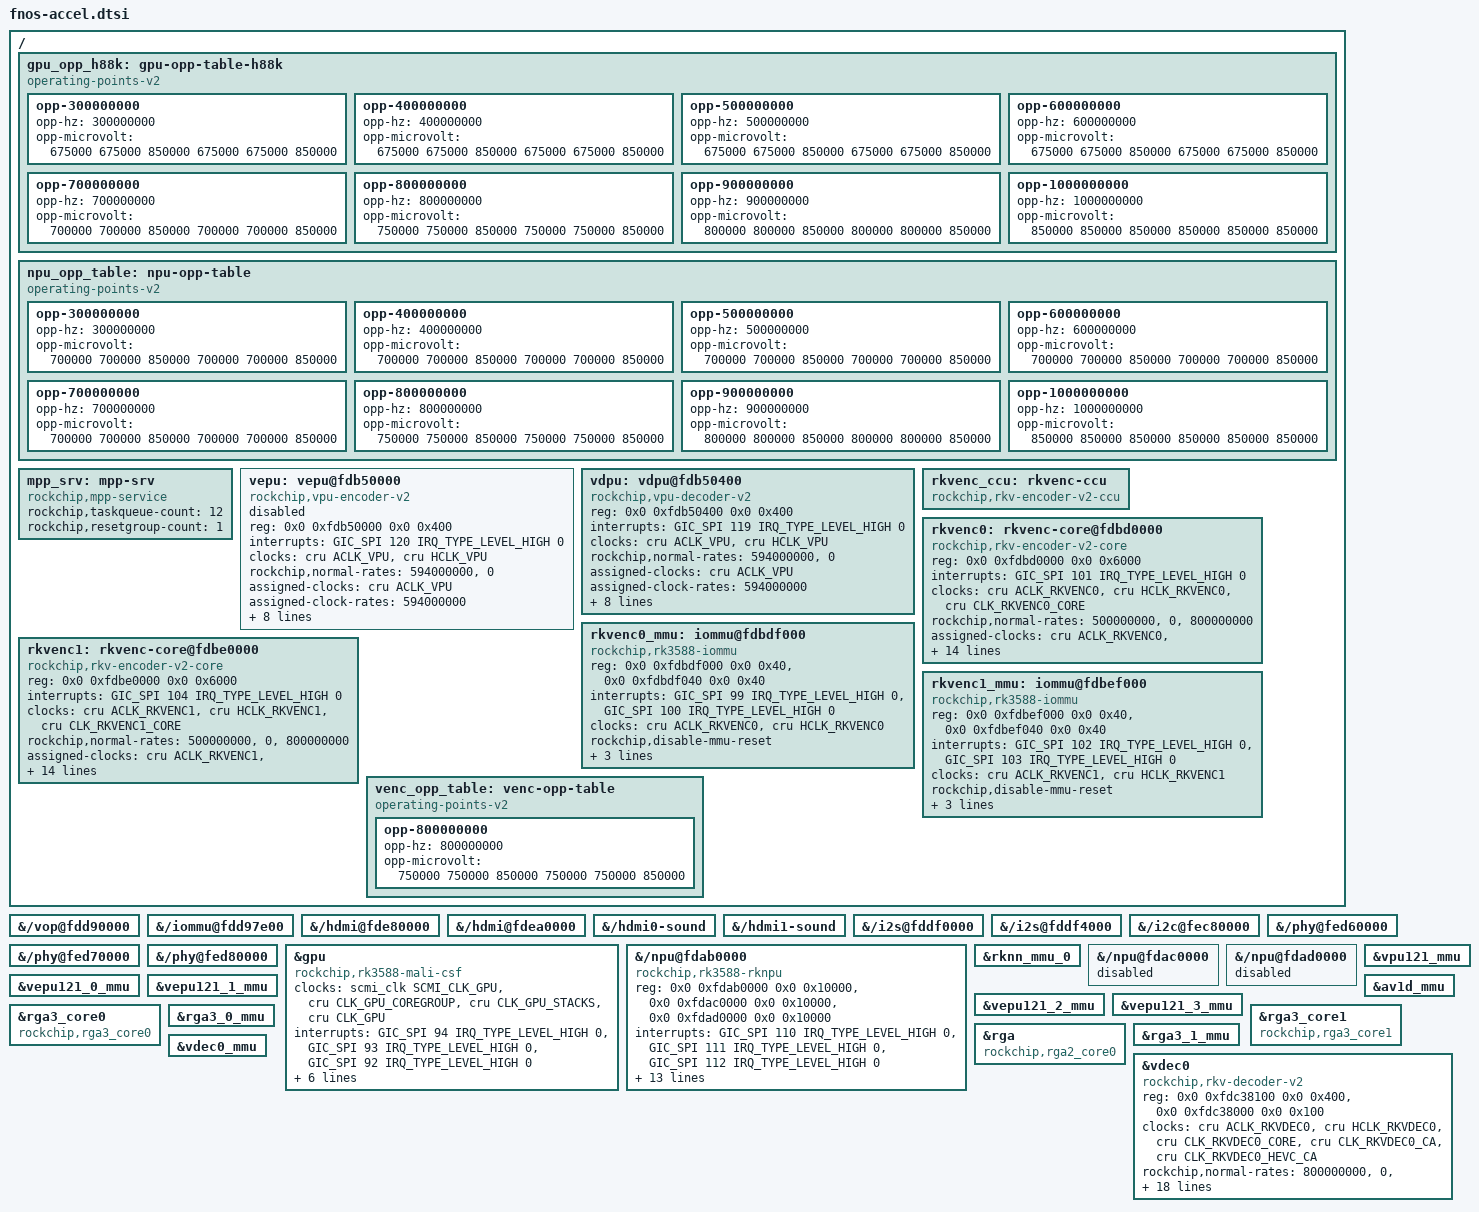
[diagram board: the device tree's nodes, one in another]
/* 对齐「真·官方 T6 DTB」的多媒体/加速器节点。
 *
 * 依据（2026-10-27 实机取证，refs/t6-official.dtb = t6.img p1 原件，sha256 09425cc7…）：
 *   飞牛内核 6.18.18.c1145-trim 的多媒体驱动是 Rockchip BSP 树外模块：
 *     updates/trim/rk_gpu/rkgpu_bifrost_csf.ko   of_match = rockchip,rk3588-mali-csf / arm,mali-valhall
 *     updates/trim/rk_vcodec/rknpu.ko            of_match = rockchip,rk3588-rknpu
 *     updates/trim/rk_vcodec/rk_vcodec.ko        of_match = rockchip,mpp-service（顶层 mpp-srv 节点）
 *     updates/trim/rk_vcodec/rga3.ko             of_match = rockchip,rga3_core0 / rga3_core1 / rga2_core0
 *   而主线 rk3588-base.dtsi 写的是 arm,mali-valhall-csf / rockchip,rk3588-rknn-core /
 *   rockchip,rk3588-rga3，且完全没有 mpp-srv 节点 —— 于是三个驱动都注册成功却 0 设备绑定，
 *   表现为：无 /dev/dri、无 /dev/rknpu、无 /dev/mpp_service。
 *   本文件把这些节点按真 T6 DTB 的命名/属性/中断顺序覆盖回来（硬件地址、时钟、电源域
 *   与主线 dtsi 一致，只改驱动认得的命名与必需属性）。
 */

/* ---------------- 显示通路（保持开启） ---------------- */
&{/vop@fdd90000} { status = "okay"; };
&{/iommu@fdd97e00} { status = "okay"; };
&{/hdmi@fde80000} { status = "okay"; };
&{/hdmi@fdea0000} { status = "okay"; };
&{/hdmi0-sound} { status = "okay"; };
&{/hdmi1-sound} { status = "okay"; };
&{/i2s@fddf0000} { status = "okay"; };
&{/i2s@fddf4000} { status = "okay"; };
&{/i2c@fec80000} { status = "okay"; };
&{/phy@fed60000} { status = "okay"; };
&{/phy@fed70000} { status = "okay"; };
&{/phy@fed80000} { status = "okay"; };

/* ---------------- GPU：BSP kbase (Bifrost CSF) ----------------
 * 真 T6：compatible = rockchip,rk3588-mali-csf + arm,mali-valhall
 *        clock-names = clk_mali / clk_gpu_coregroup / clk_gpu_stacks / clk_gpu  （4 个）
 *        interrupt-names = GPU / MMU / JOB （对应 SPI 94 / 93 / 92）
 *        mali-supply / mem-supply = vdd_gpu_s0
 */
&gpu {
	compatible = "rockchip,rk3588-mali-csf", "arm,mali-valhall";
	clocks = <&scmi_clk SCMI_CLK_GPU>, <&cru CLK_GPU_COREGROUP>,
		 <&cru CLK_GPU_STACKS>, <&cru CLK_GPU>;
	clock-names = "clk_mali", "clk_gpu_coregroup", "clk_gpu_stacks", "clk_gpu";
	interrupts = <GIC_SPI 94 IRQ_TYPE_LEVEL_HIGH 0>,
		     <GIC_SPI 93 IRQ_TYPE_LEVEL_HIGH 0>,
		     <GIC_SPI 92 IRQ_TYPE_LEVEL_HIGH 0>;
	interrupt-names = "GPU", "MMU", "JOB";
	mali-supply = <&vdd_gpu_s0>;
	mem-supply = <&vdd_gpu_s0>;
	upthreshold = <60>;
	downdifferential = <30>;
	power-off-delay-ms = <200>;
	operating-points-v2 = <&gpu_opp_h88k>;
	status = "okay";
};

/* GPU 的 opp 表：照官方 T6 的 /gpu-opp-table（8 档，microvolt 6 值＝mali-supply + mem-supply
 * 各 min/target/max）。缺这张表 GPU 报 _of_add_opp_table_v2: Failed to add OPP, -22。
 */
/ {
	gpu_opp_h88k: gpu-opp-table-h88k {
		compatible = "operating-points-v2";
		opp-300000000  { opp-hz = /bits/ 64 <300000000>;  opp-microvolt = <675000 675000 850000 675000 675000 850000>; };
		opp-400000000  { opp-hz = /bits/ 64 <400000000>;  opp-microvolt = <675000 675000 850000 675000 675000 850000>; };
		opp-500000000  { opp-hz = /bits/ 64 <500000000>;  opp-microvolt = <675000 675000 850000 675000 675000 850000>; };
		opp-600000000  { opp-hz = /bits/ 64 <600000000>;  opp-microvolt = <675000 675000 850000 675000 675000 850000>; };
		opp-700000000  { opp-hz = /bits/ 64 <700000000>;  opp-microvolt = <700000 700000 850000 700000 700000 850000>; };
		opp-800000000  { opp-hz = /bits/ 64 <800000000>;  opp-microvolt = <750000 750000 850000 750000 750000 850000>; };
		opp-900000000  { opp-hz = /bits/ 64 <900000000>;  opp-microvolt = <800000 800000 850000 800000 800000 850000>; };
		opp-1000000000 { opp-hz = /bits/ 64 <1000000000>; opp-microvolt = <850000 850000 850000 850000 850000 850000>; };
	};
};


/ {
	npu_opp_table: npu-opp-table {
		compatible = "operating-points-v2";
		/* 数值照官方 T6 DTB 的 npu-opp-table（supported-hw=0xe9 那一组基础档；
		 * pvtm/nvmem 校准属性省略——本板 efuse 里没有 npu-opp-info 子节点） */
		opp-300000000  { opp-hz = /bits/ 64 <300000000>;  opp-microvolt = <700000 700000 850000 700000 700000 850000>; };
		opp-400000000  { opp-hz = /bits/ 64 <400000000>;  opp-microvolt = <700000 700000 850000 700000 700000 850000>; };
		opp-500000000  { opp-hz = /bits/ 64 <500000000>;  opp-microvolt = <700000 700000 850000 700000 700000 850000>; };
		opp-600000000  { opp-hz = /bits/ 64 <600000000>;  opp-microvolt = <700000 700000 850000 700000 700000 850000>; };
		opp-700000000  { opp-hz = /bits/ 64 <700000000>;  opp-microvolt = <700000 700000 850000 700000 700000 850000>; };
		opp-800000000  { opp-hz = /bits/ 64 <800000000>;  opp-microvolt = <750000 750000 850000 750000 750000 850000>; };
		opp-900000000  { opp-hz = /bits/ 64 <900000000>;  opp-microvolt = <800000 800000 850000 800000 800000 850000>; };
		opp-1000000000 { opp-hz = /bits/ 64 <1000000000>; opp-microvolt = <850000 850000 850000 850000 850000 850000>; };
	};
};

/* ---------------- NPU：BSP rknpu（三核一个设备） ----------------
 * 真 T6：compatible = rockchip,rk3588-rknpu；reg 三段各 64KiB（pc/cna/core）；
 *        3 个中断、8 个时钟、6 个复位、3 个电源域。
 */
&{/npu@fdab0000} {
	compatible = "rockchip,rk3588-rknpu";
	reg = <0x0 0xfdab0000 0x0 0x10000>,
	      <0x0 0xfdac0000 0x0 0x10000>,
	      <0x0 0xfdad0000 0x0 0x10000>;
	reg-names = "pc", "cna", "core";
	interrupts = <GIC_SPI 110 IRQ_TYPE_LEVEL_HIGH 0>,
		     <GIC_SPI 111 IRQ_TYPE_LEVEL_HIGH 0>,
		     <GIC_SPI 112 IRQ_TYPE_LEVEL_HIGH 0>;
	interrupt-names = "npu0_irq", "npu1_irq", "npu2_irq";
	clocks = <&scmi_clk SCMI_CLK_NPU>,
		 <&cru ACLK_NPU0>, <&cru ACLK_NPU1>, <&cru ACLK_NPU2>,
		 <&cru HCLK_NPU0>, <&cru HCLK_NPU1>, <&cru HCLK_NPU2>,
		 <&cru PCLK_NPU_ROOT>;
	clock-names = "clk_npu", "aclk0", "aclk1", "aclk2",
		      "hclk0", "hclk1", "hclk2", "pclk";
	resets = <&cru SRST_A_RKNN0>, <&cru SRST_A_RKNN1>, <&cru SRST_A_RKNN2>,
		 <&cru SRST_H_RKNN0>, <&cru SRST_H_RKNN1>, <&cru SRST_H_RKNN2>;
	reset-names = "srst_a0", "srst_a1", "srst_a2", "srst_h0", "srst_h1", "srst_h2";
	power-domains = <&power RK3588_PD_NPUTOP>, <&power RK3588_PD_NPU1>,
			<&power RK3588_PD_NPU2>;
	power-domain-names = "npu0", "npu1", "npu2";
	iommus = <&rknn_mmu_0>;
	rknpu-supply = <&vdd_npu_s0>;
	mem-supply = <&vdd_npu_s0>;
	operating-points-v2 = <&npu_opp_table>;
	status = "okay";
};

&rknn_mmu_0 { status = "okay"; };
/* 独立的两颗核节点不再单独启用（BSP 驱动把三核当一个设备） */
&{/npu@fdac0000} { status = "disabled"; };
&{/npu@fdad0000} { status = "disabled"; };

/* ---------------- VPU / MPP 服务 ----------------
 * rk_vcodec.ko 只认顶层 mpp-srv（rockchip,mpp-service），
 * 主线 dtsi 完全没有这个节点 → /dev/mpp_service 永远不出现。
 */
/ {
	mpp_srv: mpp-srv {
		compatible = "rockchip,mpp-service";
		rockchip,taskqueue-count = <12>;
		rockchip,resetgroup-count = <1>;
		status = "okay";
	};
};

/* 各编解码核的 IOMMU 全开（真 T6 里都是 okay） */
&vpu121_mmu { status = "okay"; };
&vepu121_0_mmu { status = "okay"; };
&vepu121_1_mmu { status = "okay"; };
&vepu121_2_mmu { status = "okay"; };
&vepu121_3_mmu { status = "okay"; };
&av1d_mmu { status = "okay"; };

/* ---------------- RGA：BSP rga3 ----------------
 * 真 T6：fdb60000 = rga3_core0、fdb70000 = rga3_core1、fdb80000 = rga2_core0，
 *        时钟名 aclk_rga3_0 / hclk_rga3_0 / clk_rga3_0 等（主线写 aclk/hclk/sclk）。
 */
&rga3_core0 {
	compatible = "rockchip,rga3_core0";
	clock-names = "aclk_rga3_0", "hclk_rga3_0", "clk_rga3_0";
	interrupt-names = "rga3_core0_irq";
	status = "okay";
};

&rga3_core1 {
	compatible = "rockchip,rga3_core1";
	clock-names = "aclk_rga3_1", "hclk_rga3_1", "clk_rga3_1";
	interrupt-names = "rga3_core1_irq";
	status = "okay";
};

&rga {
	compatible = "rockchip,rga2_core0";
	clock-names = "aclk_rga2", "hclk_rga2", "clk_rga2";
	interrupt-names = "rga2_irq";
	status = "okay";
};

&rga3_0_mmu { status = "okay"; };
&rga3_1_mmu { status = "okay"; };

/* ---------------- VPU 解码核：MPP 新 BSP 命名（rkv-decoder-v2） ----------------
 * 飞牛 rk_vcodec.ko 的 of_match 只有抽象名（rockchip,rkv-decoder-v2 / rkv-encoder-v2 …），
 * 不认主线/T6 老 DTB 的 rockchip,rk3588-vdec。此处把 rkvdec0(fdc38000) 按 vendor 6.1
 * 的 rkvdec-core 定义重写（地址/中断/时钟/复位与主线同一块硬件，只是命名与属性名不同）。
 */
&vdec0 {
	compatible = "rockchip,rkv-decoder-v2";
	reg = <0x0 0xfdc38100 0x0 0x400>, <0x0 0xfdc38000 0x0 0x100>;
	reg-names = "regs", "link";
	interrupt-names = "irq_rkvdec0";
	clocks = <&cru ACLK_RKVDEC0>, <&cru HCLK_RKVDEC0>, <&cru CLK_RKVDEC0_CORE>,
		 <&cru CLK_RKVDEC0_CA>, <&cru CLK_RKVDEC0_HEVC_CA>;
	clock-names = "aclk_vcodec", "hclk_vcodec", "clk_core", "clk_cabac", "clk_hevc_cabac";
	rockchip,normal-rates = <800000000>, <0>, <600000000>, <600000000>, <1000000000>;
	resets = <&cru SRST_A_RKVDEC0>, <&cru SRST_H_RKVDEC0>, <&cru SRST_RKVDEC0_CORE>,
		 <&cru SRST_RKVDEC0_CA>, <&cru SRST_RKVDEC0_HEVC_CA>;
	reset-names = "video_a", "video_h", "video_core", "video_cabac", "video_hevc_cabac";
	rockchip,skip-pmu-idle-request;
	iommus = <&vdec0_mmu>;
	rockchip,srv = <&mpp_srv>;
	rockchip,core-mask = <0x00010001>;
	rockchip,task-capacity = <16>;
	rockchip,taskqueue-node = <9>;
	rockchip,sram = <&vdec0_sram>;
	rockchip,rcb-iova = <0xFFF00000 0x100000>;
	rockchip,rcb-info = <136 24576>, <137 49152>, <141 90112>, <140 49152>,
			    <139 180224>, <133 49152>, <134 8192>, <135 4352>,
			    <138 13056>, <142 291584>;
	rockchip,rcb-min-width = <512>;
	power-domains = <&power RK3588_PD_RKVDEC0>;
	status = "okay";
};

&vdec0_mmu { status = "okay"; };


/* ================= VPU 编码链：逐节点照官方 T6 DTB（refs/t6-official.dtb）=================
 * 官方 T6 里编码是 RKVENC 承担的，VEPU 本身 status=disabled：
 *   /vepu@fdb50000      disabled   （vpu-encoder-v2）
 *   /vdpu@fdb50400      okay       （vpu-decoder-v2，与 vepu 共享 0xfdb50 块）
 *   /rkvenc-ccu         okay
 *   /rkvenc-core@fdbd0000 /rkvenc-core@fdbe0000  okay + venc-supply/mem-supply = PMIC dcdc-reg4
 *   /iommu@fdbdf000 /iommu@fdbef000  okay
 *   /venc-opp-table     800MHz 750–850mV
 * 与官方的唯一差异是 phandle：官方 dcdc-reg4 在本板标签是 vdd_vdenc_s0；
 * 节点名/compatible/reg/中断/时钟/复位/速率全部照官方与 vendor 6.1 原文。
 */
/ {
	vepu: vepu@fdb50000 {
		compatible = "rockchip,vpu-encoder-v2";
		reg = <0x0 0xfdb50000 0x0 0x400>;
		interrupts = <GIC_SPI 120 IRQ_TYPE_LEVEL_HIGH 0>;
		interrupt-names = "irq_vepu";
		clocks = <&cru ACLK_VPU>, <&cru HCLK_VPU>;
		clock-names = "aclk_vcodec", "hclk_vcodec";
		rockchip,normal-rates = <594000000>, <0>;
		assigned-clocks = <&cru ACLK_VPU>;
		assigned-clock-rates = <594000000>;
		resets = <&cru SRST_A_VPU>, <&cru SRST_H_VPU>;
		reset-names = "shared_video_a", "shared_video_h";
		rockchip,skip-pmu-idle-request;
		rockchip,disable-auto-freq;
		iommus = <&vpu121_mmu>;
		rockchip,srv = <&mpp_srv>;
		rockchip,taskqueue-node = <0>;
		rockchip,resetgroup-node = <0>;
		power-domains = <&power RK3588_PD_VDPU>;
		status = "disabled";
	};

	vdpu: vdpu@fdb50400 {
		compatible = "rockchip,vpu-decoder-v2";
		reg = <0x0 0xfdb50400 0x0 0x400>;
		interrupts = <GIC_SPI 119 IRQ_TYPE_LEVEL_HIGH 0>;
		interrupt-names = "irq_vdpu";
		clocks = <&cru ACLK_VPU>, <&cru HCLK_VPU>;
		clock-names = "aclk_vcodec", "hclk_vcodec";
		rockchip,normal-rates = <594000000>, <0>;
		assigned-clocks = <&cru ACLK_VPU>;
		assigned-clock-rates = <594000000>;
		resets = <&cru SRST_A_VPU>, <&cru SRST_H_VPU>;
		reset-names = "shared_video_a", "shared_video_h";
		rockchip,skip-pmu-idle-request;
		rockchip,disable-auto-freq;
		iommus = <&vpu121_mmu>;
		rockchip,srv = <&mpp_srv>;
		rockchip,taskqueue-node = <0>;
		rockchip,resetgroup-node = <0>;
		power-domains = <&power RK3588_PD_VDPU>;
		status = "okay";
	};

	rkvenc_ccu: rkvenc-ccu {
		compatible = "rockchip,rkv-encoder-v2-ccu";
		status = "okay";
	};

	rkvenc0: rkvenc-core@fdbd0000 {
		compatible = "rockchip,rkv-encoder-v2-core";
		reg = <0x0 0xfdbd0000 0x0 0x6000>;
		interrupts = <GIC_SPI 101 IRQ_TYPE_LEVEL_HIGH 0>;
		interrupt-names = "irq_rkvenc0";
		clocks = <&cru ACLK_RKVENC0>, <&cru HCLK_RKVENC0>, <&cru CLK_RKVENC0_CORE>;
		clock-names = "aclk_vcodec", "hclk_vcodec", "clk_core";
		rockchip,normal-rates = <500000000>, <0>, <800000000>;
		assigned-clocks = <&cru ACLK_RKVENC0>, <&cru CLK_RKVENC0_CORE>;
		assigned-clock-rates = <500000000>, <800000000>;
		resets = <&cru SRST_A_RKVENC0>, <&cru SRST_H_RKVENC0>, <&cru SRST_RKVENC0_CORE>;
		reset-names = "video_a", "video_h", "video_core";
		rockchip,skip-pmu-idle-request;
		iommus = <&rkvenc0_mmu>;
		rockchip,srv = <&mpp_srv>;
		rockchip,ccu = <&rkvenc_ccu>;
		rockchip,taskqueue-node = <7>;
		rockchip,task-capacity = <8>;
		power-domains = <&power RK3588_PD_VENC0>;
		operating-points-v2 = <&venc_opp_table>;
		venc-supply = <&vdd_vdenc_s0>;
		mem-supply = <&vdd_vdenc_s0>;
		status = "okay";
	};

	rkvenc1: rkvenc-core@fdbe0000 {
		compatible = "rockchip,rkv-encoder-v2-core";
		reg = <0x0 0xfdbe0000 0x0 0x6000>;
		interrupts = <GIC_SPI 104 IRQ_TYPE_LEVEL_HIGH 0>;
		interrupt-names = "irq_rkvenc1";
		clocks = <&cru ACLK_RKVENC1>, <&cru HCLK_RKVENC1>, <&cru CLK_RKVENC1_CORE>;
		clock-names = "aclk_vcodec", "hclk_vcodec", "clk_core";
		rockchip,normal-rates = <500000000>, <0>, <800000000>;
		assigned-clocks = <&cru ACLK_RKVENC1>, <&cru CLK_RKVENC1_CORE>;
		assigned-clock-rates = <500000000>, <800000000>;
		resets = <&cru SRST_A_RKVENC1>, <&cru SRST_H_RKVENC1>, <&cru SRST_RKVENC1_CORE>;
		reset-names = "video_a", "video_h", "video_core";
		rockchip,skip-pmu-idle-request;
		iommus = <&rkvenc1_mmu>;
		rockchip,srv = <&mpp_srv>;
		rockchip,ccu = <&rkvenc_ccu>;
		rockchip,taskqueue-node = <7>;
		rockchip,task-capacity = <8>;
		power-domains = <&power RK3588_PD_VENC1>;
		operating-points-v2 = <&venc_opp_table>;
		venc-supply = <&vdd_vdenc_s0>;
		mem-supply = <&vdd_vdenc_s0>;
		status = "okay";
	};

	rkvenc0_mmu: iommu@fdbdf000 {
		compatible = "rockchip,rk3588-iommu", "rockchip,rk3568-iommu";
		reg = <0x0 0xfdbdf000 0x0 0x40>, <0x0 0xfdbdf040 0x0 0x40>;
		interrupts = <GIC_SPI 99 IRQ_TYPE_LEVEL_HIGH 0>,
			     <GIC_SPI 100 IRQ_TYPE_LEVEL_HIGH 0>;
		interrupt-names = "irq_rkvenc0_mmu0", "irq_rkvenc0_mmu1";
		clocks = <&cru ACLK_RKVENC0>, <&cru HCLK_RKVENC0>;
		clock-names = "aclk", "iface";
		rockchip,disable-mmu-reset;
		rockchip,enable-cmd-retry;
		rockchip,shootdown-entire;
		#iommu-cells = <0>;
		power-domains = <&power RK3588_PD_VENC0>;
		status = "okay";
	};

	rkvenc1_mmu: iommu@fdbef000 {
		compatible = "rockchip,rk3588-iommu", "rockchip,rk3568-iommu";
		reg = <0x0 0xfdbef000 0x0 0x40>, <0x0 0xfdbef040 0x0 0x40>;
		interrupts = <GIC_SPI 102 IRQ_TYPE_LEVEL_HIGH 0>,
			     <GIC_SPI 103 IRQ_TYPE_LEVEL_HIGH 0>;
		interrupt-names = "irq_rkvenc1_mmu0", "irq_rkvenc1_mmu1";
		clocks = <&cru ACLK_RKVENC1>, <&cru HCLK_RKVENC1>;
		clock-names = "aclk", "iface";
		rockchip,disable-mmu-reset;
		rockchip,enable-cmd-retry;
		rockchip,shootdown-entire;
		#iommu-cells = <0>;
		power-domains = <&power RK3588_PD_VENC1>;
		status = "okay";
	};

	venc_opp_table: venc-opp-table {
		compatible = "operating-points-v2";
		opp-800000000 {
			opp-hz = /bits/ 64 <800000000>;
			opp-microvolt = <750000 750000 850000 750000 750000 850000>;
		};
	};
};
